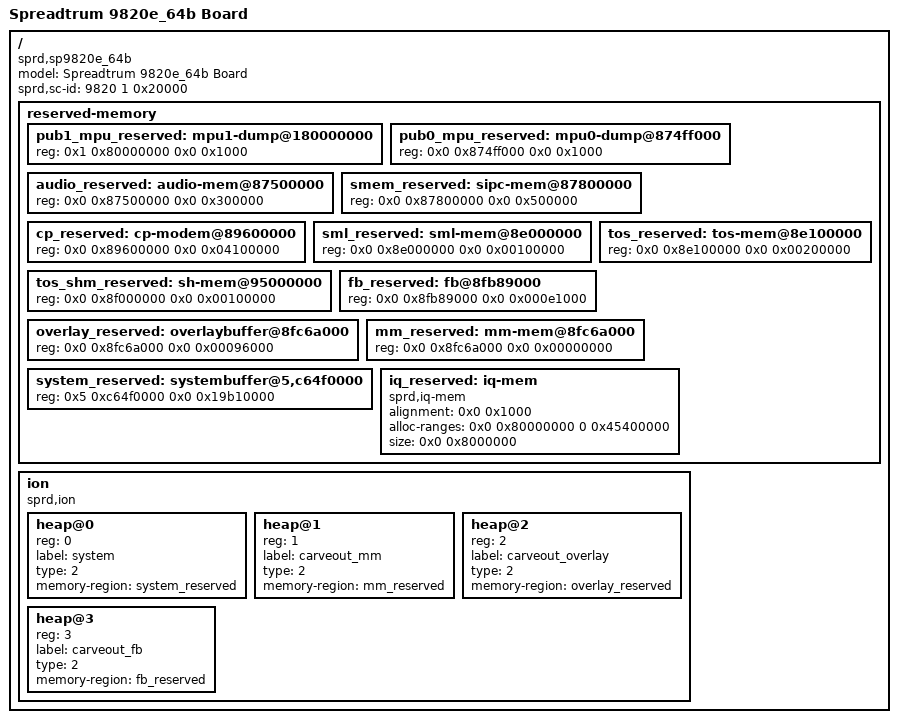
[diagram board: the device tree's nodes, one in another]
/*
 * Spreadtrum SP9860g board DTS file
 *
 * Copyright (C) 2016, Spreadtrum Communications Inc.
 *
 * This file is licensed under a dual GPLv2 or X11 license.
 */

/dts-v1/;

/ {
	model = "Spreadtrum 9820e_64b Board";

	compatible = "sprd,sp9820e_64b";

	sprd,sc-id = <9820 1 0x20000>;

	reserved-memory {
		#address-cells = <2>;
		#size-cells = <2>;
		ranges;

		pub1_mpu_reserved: mpu1-dump@180000000 {
			reg = <0x1 0x80000000 0x0 0x1000>;
		};

		pub0_mpu_reserved: mpu0-dump@874ff000 {
			reg = <0x0 0x874ff000 0x0 0x1000>;
		};

		audio_reserved: audio-mem@87500000 {
			reg = <0x0 0x87500000 0x0 0x300000>;
		};

		smem_reserved: sipc-mem@87800000 {
			reg = <0x0 0x87800000 0x0 0x500000>;
		};

                cp_reserved: cp-modem@89600000 {
                        reg = <0x0 0x89600000 0x0 0x04100000>;
                };

                /* must be 64M aligned */
                sml_reserved: sml-mem@8e000000{
                        reg = <0x0 0x8e000000 0x0 0x00100000>;
                };

                tos_reserved: tos-mem@8e100000{
                        reg = <0x0 0x8e100000 0x0 0x00200000>;
                };

		tos_shm_reserved: sh-mem@95000000{
			reg = <0x0 0x8f000000 0x0 0x00100000>;
		};

                fb_reserved: fb@8fb89000{
                        reg = <0x0 0x8fb89000 0x0 0x000e1000>;
                };

                overlay_reserved: overlaybuffer@8fc6a000{
                        reg = <0x0 0x8fc6a000 0x0 0x00096000>;
                };

                mm_reserved: mm-mem@8fc6a000{
                        reg = <0x0 0x8fc6a000 0x0 0x00000000>;
                };

		system_reserved: systembuffer@5,c64f0000{
			reg = <0x5 0xc64f0000 0x0 0x19b10000>;
		};

		iq_reserved: iq-mem{
			compatible = "sprd,iq-mem";
			alignment = <0x0 0x1000>;
			alloc-ranges = <0x0 0x80000000 0 0x45400000>;
			size = <0x0 0x8000000>;
		};
	};


	ion {
		compatible = "sprd,ion";
		#address-cells = <1>;
		#size-cells = <0>;

		heap@0 {
			reg = <0>;
			label = "system";
			type = <2>;
			memory-region = <&system_reserved>;
		};

		heap@1 {
			reg = <1>;
			label = "carveout_mm";
			type = <2>;
			memory-region = <&mm_reserved>;
		};

		heap@2 {
			reg = <2>;
			label = "carveout_overlay";
			type = <2>;
			memory-region = <&overlay_reserved>;
		};

		heap@3 {
			reg = <3>;
			label = "carveout_fb";
			type = <2>;
			memory-region = <&fb_reserved>;
		};
	};
};
